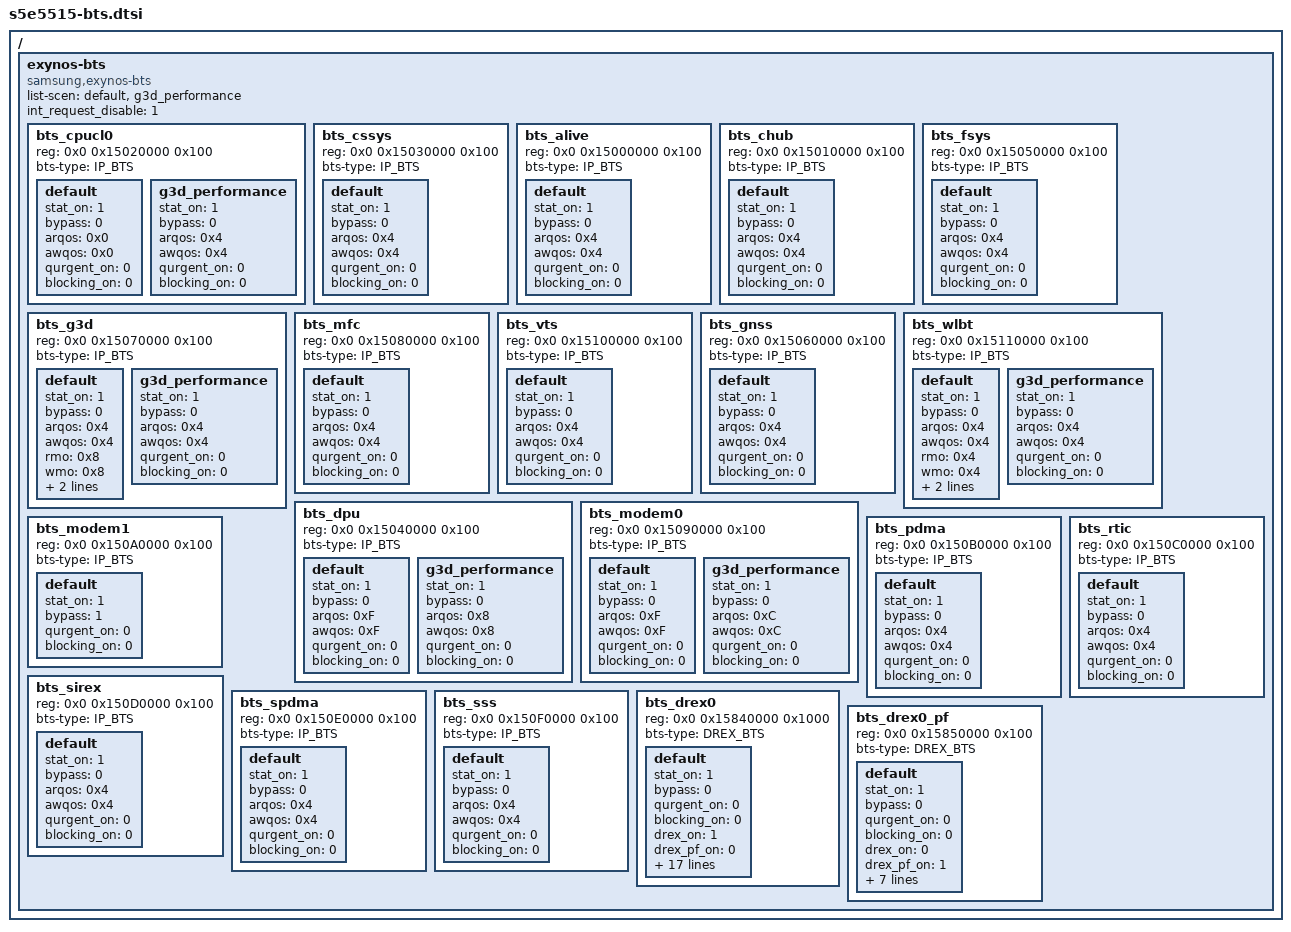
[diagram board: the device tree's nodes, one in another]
/*
 * SAMSUNG EXYNOS SoC BTS device tree source
 *
 * Copyright (c) 2018 Samsung Electronics Co., Ltd.
 *		http://www.samsung.com
 *
 * SAMSUNG EXYNOS SoC BTS device nodes are listed in this file.
 * EXYNOS based board files should include this file.
 *
 * This program is free software; you can redistribute it and/or modify
 * it under the terms of the GNU General Public License version 2 as
 * published by the Free Software Foundation.
 *
 */

#include <dt-bindings/soc/samsung/exynos-bts.h>

/ {
	exynos-bts {
		compatible = "samsung,exynos-bts";
		#address-cells = <2>;
		#size-cells = <1>;
		ranges;

		list-scen = "default",
			    "g3d_performance";

		int_request_disable = <1>;

		bts_cpucl0 {
			reg = <0x0 0x15020000 0x100>;
			status = "okay";
			bts-type = <IP_BTS>;
			default {
				stat_on = <1>;
				bypass = <0>;
				arqos = <0x0>;
				awqos = <0x0>;
				qurgent_on = <0>;
				blocking_on = <0>;
			};
			g3d_performance {
				stat_on = <1>;
				bypass = <0>;
				arqos = <0x4>;
				awqos = <0x4>;
				qurgent_on = <0>;
				blocking_on = <0>;
			};
		};
		bts_cssys {
			reg = <0x0 0x15030000 0x100>;
			status = "okay";
			bts-type = <IP_BTS>;
			default {
				stat_on = <1>;
				bypass = <0>;
				arqos = <0x4>;
				awqos = <0x4>;
				qurgent_on = <0>;
				blocking_on = <0>;
			};
		};
		bts_alive {
			reg = <0x0 0x15000000 0x100>;
			status = "okay";
			bts-type = <IP_BTS>;
			default {
				stat_on = <1>;
				bypass = <0>;
				arqos = <0x4>;
				awqos = <0x4>;
				qurgent_on = <0>;
				blocking_on = <0>;
			};
		};
		bts_chub {
			reg = <0x0 0x15010000 0x100>;
			status = "okay";
			bts-type = <IP_BTS>;
			default {
				stat_on = <1>;
				bypass = <0>;
				arqos = <0x4>;
				awqos = <0x4>;
				qurgent_on = <0>;
				blocking_on = <0>;
			};
		};
		bts_fsys {
			reg = <0x0 0x15050000 0x100>;
			status = "okay";
			bts-type = <IP_BTS>;
			default {
				stat_on = <1>;
				bypass = <0>;
				arqos = <0x4>;
				awqos = <0x4>;
				qurgent_on = <0>;
				blocking_on = <0>;
			};
		};
		bts_g3d {
			reg = <0x0 0x15070000 0x100>;
			status = "okay";
			bts-type = <IP_BTS>;
			default {
				stat_on = <1>;
				bypass = <0>;
				arqos = <0x4>;
				awqos = <0x4>;
				rmo = <0x8>;
				wmo = <0x8>;
				qurgent_on = <0>;
				blocking_on = <0>;
			};
			g3d_performance {
				stat_on = <1>;
				bypass = <0>;
				arqos = <0x4>;
				awqos = <0x4>;
				qurgent_on = <0>;
				blocking_on = <0>;
			};
		};
		bts_mfc {
			reg = <0x0 0x15080000 0x100>;
			status = "okay";
			bts-type = <IP_BTS>;
			default {
				stat_on = <1>;
				bypass = <0>;
				arqos = <0x4>;
				awqos = <0x4>;
				qurgent_on = <0>;
				blocking_on = <0>;
			};
		};
		bts_vts {
			reg = <0x0 0x15100000 0x100>;
			status = "okay";
			bts-type = <IP_BTS>;
			default {
				stat_on = <1>;
				bypass = <0>;
				arqos = <0x4>;
				awqos = <0x4>;
				qurgent_on = <0>;
				blocking_on = <0>;
			};
		};
		bts_gnss {
			reg = <0x0 0x15060000 0x100>;
			status = "okay";
			bts-type = <IP_BTS>;
			default {
				stat_on = <1>;
				bypass = <0>;
				arqos = <0x4>;
				awqos = <0x4>;
				qurgent_on = <0>;
				blocking_on = <0>;
			};
		};
		bts_wlbt {
			reg = <0x0 0x15110000 0x100>;
			status = "okay";
			bts-type = <IP_BTS>;
			default {
				stat_on = <1>;
				bypass = <0>;
				arqos = <0x4>;
				awqos = <0x4>;
				rmo = <0x4>;
				wmo = <0x4>;
				qurgent_on = <0>;
				blocking_on = <0>;
			};
			g3d_performance {
				stat_on = <1>;
				bypass = <0>;
				arqos = <0x4>;
				awqos = <0x4>;
				qurgent_on = <0>;
				blocking_on = <0>;
			};
		};
		bts_dpu {
			reg = <0x0 0x15040000 0x100>;
			status = "okay";
			bts-type = <IP_BTS>;
			default {
				stat_on = <1>;
				bypass = <0>;
				arqos = <0xF>;
				awqos = <0xF>;
				qurgent_on = <0>;
				blocking_on = <0>;
			};
			g3d_performance {
				stat_on = <1>;
				bypass = <0>;
				arqos = <0x8>;
				awqos = <0x8>;
				qurgent_on = <0>;
				blocking_on = <0>;
			};
		};
		bts_modem0 {
			reg = <0x0 0x15090000 0x100>;
			status = "okay";
			bts-type = <IP_BTS>;
			default {
				stat_on = <1>;
				bypass = <0>;
				arqos = <0xF>;
				awqos = <0xF>;
				qurgent_on = <0>;
				blocking_on = <0>;
			};
			g3d_performance {
				stat_on = <1>;
				bypass = <0>;
				arqos = <0xC>;
				awqos = <0xC>;
				qurgent_on = <0>;
				blocking_on = <0>;
			};
		};
		bts_modem1 {
			reg = <0x0 0x150A0000 0x100>;
			status = "okay";
			bts-type = <IP_BTS>;
			default {
				stat_on = <1>;
				bypass = <1>;
				qurgent_on = <0>;
				blocking_on = <0>;
			};
		};
		bts_pdma {
			reg = <0x0 0x150B0000 0x100>;
			status = "okay";
			bts-type = <IP_BTS>;
			default {
				stat_on = <1>;
				bypass = <0>;
				arqos = <0x4>;
				awqos = <0x4>;
				qurgent_on = <0>;
				blocking_on = <0>;
			};
		};
		bts_rtic {
			reg = <0x0 0x150C0000 0x100>;
			status = "okay";
			bts-type = <IP_BTS>;
			default {
				stat_on = <1>;
				bypass = <0>;
				arqos = <0x4>;
				awqos = <0x4>;
				qurgent_on = <0>;
				blocking_on = <0>;
			};
		};
		bts_sirex {
			reg = <0x0 0x150D0000 0x100>;
			status = "okay";
			bts-type = <IP_BTS>;
			default {
				stat_on = <1>;
				bypass = <0>;
				arqos = <0x4>;
				awqos = <0x4>;
				qurgent_on = <0>;
				blocking_on = <0>;
			};
		};
		bts_spdma {
			reg = <0x0 0x150E0000 0x100>;
			status = "okay";
			bts-type = <IP_BTS>;
			default {
				stat_on = <1>;
				bypass = <0>;
				arqos = <0x4>;
				awqos = <0x4>;
				qurgent_on = <0>;
				blocking_on = <0>;
			};
		};
		bts_sss {
			reg = <0x0 0x150F0000 0x100>;
			status = "okay";
			bts-type = <IP_BTS>;
			default {
				stat_on = <1>;
				bypass = <0>;
				arqos = <0x4>;
				awqos = <0x4>;
				qurgent_on = <0>;
				blocking_on = <0>;
			};
		};

		bts_drex0 {
			reg = <0x0 0x15840000 0x1000>;
			status = "okay";
			bts-type = <DREX_BTS>;
			default {
				stat_on = <1>;
				bypass = <0>;
				qurgent_on = <0>;
				blocking_on = <0>;
				drex_on = <1>;
				drex_pf_on = <0>;
				tick_granularity_s0 = <0x00000010>;
				tick_granularity_s1 = <0x00000010>;
				write_flush_config_0 = <0x50101002>;
				write_flush_config_1 = <0x1010100A>;
				drex_timeout = <0x00400100>,
					     <0x003000C0>,
					     <0x00240090>,
					     <0x001C0070>,
					     <0x00150054>,
					     <0x00100040>,
					     <0x000C0030>,
					     <0x00080020>,
					     <0x0003000E>,
					     <0x0003000C>,
					     <0x0002000A>,
					     <0x00020008>,
					     <0x00010006>,
					     <0x00010004>,
					     <0x00010002>,
					     <0x00010001>;
				vc_timer_th = <0x00480060>,
					    <0x002A0036>,
					    <0x00180020>,
					    <0x000A0010>,
					    <0x00060007>,
					    <0x00040005>,
					    <0x00020003>,
					    <0x00010001>;
				cutoff_con = <0x00000005>;
				brb_cutoff_con = <0x00080008>;
				emergent_config_r = <0x00FF0000>;
				emergent_config_w = <0x00FF0000>;
			};
		};
		bts_drex0_pf {
			reg = <0x0 0x15850000 0x100>;
			status = "okay";
			bts-type = <DREX_BTS>;
			default {
				stat_on = <1>;
				bypass = <0>;
				qurgent_on = <0>;
				blocking_on = <0>;
				drex_on = <0>;
				drex_pf_on = <1>;
				pf_token_control = <0x0000000F>;
				pf_token_threshold = <0x00040104>;
				pf_tick_granularity_s0 = <0x00000010>;
				pf_tick_granularity_s1 = <0x00000010>;
				pf_qos_timer = <0x00040004>,
					     <0x00040004>,
					     <0x00030003>,
					     <0x00030003>,
					     <0x00030003>,
					     <0x00030003>,
					     <0x00020002>,
					     <0x00010002>;
			};
		};
	};
};
